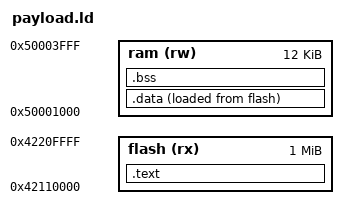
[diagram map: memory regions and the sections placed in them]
/*
 * This file is part of AtomVM.
 *
 * Copyright 2026 Peter M <petermm@gmail.com>
 *
 * Licensed under the Apache License, Version 2.0 (the "License");
 * you may not use this file except in compliance with the License.
 * You may obtain a copy of the License at
 *
 *    http://www.apache.org/licenses/LICENSE-2.0
 *
 * Unless required by applicable law or agreed to in writing, software
 * distributed under the License is distributed on an "AS IS" BASIS,
 * WITHOUT WARRANTIES OR CONDITIONS OF ANY KIND, either express or implied.
 * See the License for the specific language governing permissions and
 * limitations under the License.
 *
 * SPDX-License-Identifier: Apache-2.0 OR LGPL-2.1-or-later
 */

OUTPUT_ARCH(riscv)
ENTRY(payload_main)

MEMORY
{
    flash (rx) : ORIGIN = 0x42110000, LENGTH = 1M
    ram   (rw) : ORIGIN = 0x50001000, LENGTH = 12K
}

SECTIONS
{
    .text : ALIGN(4)
    {
        _stext = .;
        *(.text.entry)          
        *(.text)
        *(.text.*)
        *(.rodata)
        *(.rodata.*)
        *(.srodata)
        *(.srodata.*)
        _etext = .;
    } > flash

    .data : ALIGN(4)
    {
        _sdata = .;
        *(.data)
        *(.data.*)
        *(.sdata)
        *(.sdata.*)
        _edata = .;
    } > ram AT > flash

    _sidata = LOADADDR(.data);

    .bss : ALIGN(4)
    {
        _sbss = .;
        *(.bss)
        *(.bss.*)
        *(.sbss)
        *(.sbss.*)
        *(COMMON)
        _ebss = .;
    } > ram

    /DISCARD/ :
    {
        *(.comment)
        *(.eh_frame)
        *(.eh_frame_hdr)
        *(.debug_*)
    }
}
